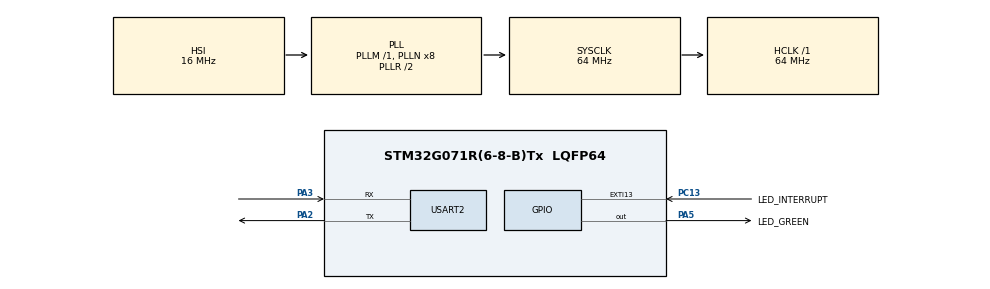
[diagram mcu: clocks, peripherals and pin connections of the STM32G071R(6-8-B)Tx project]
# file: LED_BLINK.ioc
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Mcu.Family=STM32G0
Mcu.Name=STM32G071R(6-8-B)Tx
Mcu.Package=LQFP64
NVIC.EXTI4_15_IRQn=true\:0\:0\:false\:false\:true\:true\:true\:true
NVIC.USART2_IRQn=true\:0\:0\:false\:false\:true\:true\:true\:true
PA13.GPIO_Label=TMS
PA13.Mode=Serial_Wire
PA13.Signal=SYS_SWDIO
PA14-BOOT0.GPIO_Label=TCK
PA14-BOOT0.Mode=Serial_Wire
PA14-BOOT0.Signal=SYS_SWCLK
PA2.Mode=Asynchronous
PA2.Signal=USART2_TX
PA3.Mode=Asynchronous
PA3.Signal=USART2_RX
PA5.GPIO_Label=LED_GREEN
PA5.GPIO_Speed=GPIO_SPEED_FREQ_LOW
PA5.Signal=GPIO_Output
PC13.GPIO_Label=LED_INTERRUPT
PC13.GPIO_ModeDefaultEXTI=GPIO_MODE_IT_FALLING
PC13.Signal=GPXTI13
PC14-OSC32_IN\ (PC14).Mode=LSE-External-Oscillator
PC14-OSC32_IN\ (PC14).Signal=RCC_OSC32_IN
PC15-OSC32_OUT\ (PC15).Mode=LSE-External-Oscillator
PC15-OSC32_OUT\ (PC15).Signal=RCC_OSC32_OUT
ProjectManager.HeapSize=0x200
ProjectManager.StackSize=0x400
ProjectManager.TargetToolchain=STM32CubeIDE
RCC.ADCFreq_Value=64000000
RCC.AHBFreq_Value=64000000
RCC.CortexFreq_Value=64000000
RCC.EXTERNAL_CLOCK_VALUE=12288000
RCC.HCLKFreq_Value=64000000
RCC.HSE_VALUE=8000000
RCC.HSI_VALUE=16000000
RCC.SYSCLKFreq_VALUE=64000000
RCC.SYSCLKSource=RCC_SYSCLKSOURCE_PLLCLK
RCC.VCOOutputFreq_Value=128000000
USART2.VirtualMode-Asynchronous=VM_ASYNC
board=NUCLEO-G071RB

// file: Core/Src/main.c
/* USER CODE BEGIN Header */
/**
  ******************************************************************************
  * @file           : main.c
  * @brief          : Main program body
  ******************************************************************************
  * @attention
  *
  * Copyright (c) 2025 STMicroelectronics.
  * All rights reserved.
  *
  * This software is licensed under terms that can be found in the LICENSE file
  * in the root directory of this software component.
  * If no LICENSE file comes with this software, it is provided AS-IS.
  *
  ******************************************************************************
  */
/* USER CODE END Header */
#include "main.h"

UART_HandleTypeDef huart2;

/* USER CODE BEGIN PV */
	//char on[]="ON\n\r";
	//char off[]="OFF\n\r";

uint8_t flag=0;

/* USER CODE END PV */

void SystemClock_Config(void);
static void MX_GPIO_Init(void);
static void MX_USART2_UART_Init(void);

int main(void)
{

  /* MCU Configuration--------------------------------------------------------*/

  /* Reset of all peripherals, Initializes the Flash interface and the Systick. */
  HAL_Init();

  /* Configure the system clock */
  SystemClock_Config();

  /* Initialize all configured peripherals */
  MX_GPIO_Init();
  MX_USART2_UART_Init();

  /* Infinite loop */
  while (1)
  {

    /* USER CODE BEGIN 3 */
	  //toggle pin
	 // HAL_GPIO_WritePin(GPIOA,GPIO_PIN_5,GPIO_PIN_SET);
	//  HAL_Delay(1000);
	 // HAL_GPIO_WritePin(GPIOA,GPIO_PIN_5,GPIO_PIN_RESET);
	 // HAL_Delay(200);

	  if(flag==1){
		  HAL_UART_Transmit(&huart2,"Led Toggle!\n\r", 20, 100);
		  HAL_Delay(10);
		  flag=0;
	  }

  }
  /* USER CODE END 3 */
}

void SystemClock_Config(void)
{
  RCC_OscInitTypeDef RCC_OscInitStruct = {0};
  RCC_ClkInitTypeDef RCC_ClkInitStruct = {0};

  /** Configure the main internal regulator output voltage
  */
  HAL_PWREx_ControlVoltageScaling(PWR_REGULATOR_VOLTAGE_SCALE1);

  /** Initializes the RCC Oscillators according to the specified parameters
  * in the RCC_OscInitTypeDef structure.
  */
  RCC_OscInitStruct.OscillatorType = RCC_OSCILLATORTYPE_HSI;
  RCC_OscInitStruct.HSIState = RCC_HSI_ON;
  RCC_OscInitStruct.HSIDiv = RCC_HSI_DIV1;
  RCC_OscInitStruct.HSICalibrationValue = RCC_HSICALIBRATION_DEFAULT;
  RCC_OscInitStruct.PLL.PLLState = RCC_PLL_ON;
  RCC_OscInitStruct.PLL.PLLSource = RCC_PLLSOURCE_HSI;
  RCC_OscInitStruct.PLL.PLLM = RCC_PLLM_DIV1;
  RCC_OscInitStruct.PLL.PLLN = 8;
  RCC_OscInitStruct.PLL.PLLP = RCC_PLLP_DIV2;
  RCC_OscInitStruct.PLL.PLLQ = RCC_PLLQ_DIV2;
  RCC_OscInitStruct.PLL.PLLR = RCC_PLLR_DIV2;
  if (HAL_RCC_OscConfig(&RCC_OscInitStruct) != HAL_OK)
  {
    Error_Handler();
  }

  /** Initializes the CPU, AHB and APB buses clocks
  */
  RCC_ClkInitStruct.ClockType = RCC_CLOCKTYPE_HCLK|RCC_CLOCKTYPE_SYSCLK
                              |RCC_CLOCKTYPE_PCLK1;
  RCC_ClkInitStruct.SYSCLKSource = RCC_SYSCLKSOURCE_PLLCLK;
  RCC_ClkInitStruct.AHBCLKDivider = RCC_SYSCLK_DIV1;
  RCC_ClkInitStruct.APB1CLKDivider = RCC_HCLK_DIV1;

  if (HAL_RCC_ClockConfig(&RCC_ClkInitStruct, FLASH_LATENCY_2) != HAL_OK)
  {
    Error_Handler();
  }
}

static void MX_USART2_UART_Init(void)
{

  huart2.Instance = USART2;
  huart2.Init.BaudRate = 115200;
  huart2.Init.WordLength = UART_WORDLENGTH_8B;
  huart2.Init.StopBits = UART_STOPBITS_1;
  huart2.Init.Parity = UART_PARITY_NONE;
  huart2.Init.Mode = UART_MODE_TX_RX;
  huart2.Init.HwFlowCtl = UART_HWCONTROL_NONE;
  huart2.Init.OverSampling = UART_OVERSAMPLING_16;
  huart2.Init.OneBitSampling = UART_ONE_BIT_SAMPLE_DISABLE;
  huart2.Init.ClockPrescaler = UART_PRESCALER_DIV1;
  huart2.AdvancedInit.AdvFeatureInit = UART_ADVFEATURE_NO_INIT;
  if (HAL_UART_Init(&huart2) != HAL_OK)
  {
    Error_Handler();
  }
  if (HAL_UARTEx_SetTxFifoThreshold(&huart2, UART_TXFIFO_THRESHOLD_1_8) != HAL_OK)
  {
    Error_Handler();
  }
  if (HAL_UARTEx_SetRxFifoThreshold(&huart2, UART_RXFIFO_THRESHOLD_1_8) != HAL_OK)
  {
    Error_Handler();
  }
  if (HAL_UARTEx_DisableFifoMode(&huart2) != HAL_OK)
  {
    Error_Handler();
  }

}

static void MX_GPIO_Init(void)
{
  GPIO_InitTypeDef GPIO_InitStruct = {0};

  /* GPIO Ports Clock Enable */
  __HAL_RCC_GPIOC_CLK_ENABLE();
  __HAL_RCC_GPIOA_CLK_ENABLE();

  /*Configure GPIO pin Output Level */
  HAL_GPIO_WritePin(LED_GREEN_GPIO_Port, LED_GREEN_Pin, GPIO_PIN_RESET);

  /*Configure GPIO pin : LED_INTERRUPT_Pin */
  GPIO_InitStruct.Pin = LED_INTERRUPT_Pin;
  GPIO_InitStruct.Mode = GPIO_MODE_IT_FALLING;
  GPIO_InitStruct.Pull = GPIO_NOPULL;
  HAL_GPIO_Init(LED_INTERRUPT_GPIO_Port, &GPIO_InitStruct);

  /*Configure GPIO pin : LED_GREEN_Pin */
  GPIO_InitStruct.Pin = LED_GREEN_Pin;
  GPIO_InitStruct.Mode = GPIO_MODE_OUTPUT_PP;
  GPIO_InitStruct.Pull = GPIO_NOPULL;
  GPIO_InitStruct.Speed = GPIO_SPEED_FREQ_LOW;
  HAL_GPIO_Init(LED_GREEN_GPIO_Port, &GPIO_InitStruct);

  /* EXTI interrupt init*/
  HAL_NVIC_SetPriority(EXTI4_15_IRQn, 0, 0);
  HAL_NVIC_EnableIRQ(EXTI4_15_IRQn);

}

/* USER CODE BEGIN 4 */
void HAL_GPIO_EXTI_Falling_Callback(uint16_t GPIO_Pin){

	HAL_GPIO_TogglePin(GPIOA,GPIO_PIN_5);

	flag =1;
}

/* USER CODE END 4 */

void Error_Handler(void)
{
  __disable_irq();
  while (1)
  {
  }
}
